# XMC1200 register map
Vendor: Infineon; File version: 1.3.0 (Reference Manual v1.3)
CPU: CM0 r0p0, little endian, no MPU, no FPU, 2 interrupt priority bits
Registers are 32-bit, read-write, reset 0x0 unless marked. A register's access mark holds for its fields unless they carry their own. Offsets are from the block's base; [hi:lo] are bit positions.

## NVM — NVM Unit
Base 0x40050000
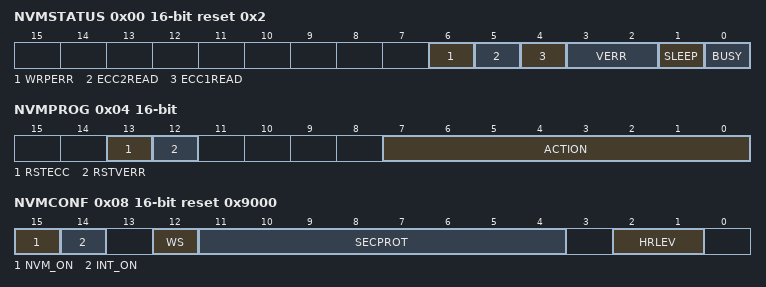
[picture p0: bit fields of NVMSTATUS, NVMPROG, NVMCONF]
0x00 NVMSTATUS 16-bit ro reset 0x2
  [6] WRPERR — Write Protocol Error
    0=No write protocol failure occurred; 1=At least one write protocol failure was detected
  [5] ECC2READ
    0=No ECC two bit failure during memory read operations; 1=At least one ECC two bit failure was detected
  [4] ECC1READ
    0=No ECC single bit failure occurred; 1=At least one ECC single bit failure was detected and corrected
  [3:2] VERR — Verify Error
    0=No fail bit; 1=One fail bit in one data block; 2=Two fail bits in two different data blocks; 3=Two or more fail bits in one data block, or three or more fail bits overall
  [1] SLEEP — Sleep Mode
    0=NVM not in sleep mode, and no sleep or wake up procedure in progress; 1=NVM in sleep mode, or busy due to a sleep or wake up procedure
  [0] BUSY
    0=The NVM is not busy. Memory reads from the cell array and register write accesses are possible.; 1=The NVM is busy. Memory reads and register write accesses are not possible.
0x04 NVMPROG 16-bit — NVM Programming Control Register
  [13] RSTECC — Reset ECC
    0=No action; 1=Reset of .ECCxREAD and NVMSTATUS.WRPERR
  [12] RSTVERR — Reset Verify Error
    0=No action; 1=Reset of .VERR
  [7:0] ACTION — ACTION: [VERIFY, ONE_SHOT, OPTYPE]
    0=Idle state, no action triggered. Writing 0x00 exits current mode.; 81=Start one-shot write operation with automatic verify; 145=Start one-shot write operation without verify; 97=Start continuous write operation with automatic verify of every write; 161=Start continuous write operation without verify; 146=Start one-shot page erase operation; 162=Start continuous page erase operation; 208=Start one-shot verify-only: Written data is compared to array content; 224=Start continuous verify-only: Written data is compared to array content
0x08 NVMCONF 16-bit reset 0x9000 — NVM Configuration Register
  [15] NVM_ON
    0=NVM is switched to or stays in sleep mode; 1=NVM is switched to or stays in normal mode
  [14] INT_ON — Interrupt On
    0=No NVM ready interrupts are generated; 1=NVM ready interrupts are generated
  [12] WS — Number of fixed Wait States
    0=0 fixed wait states; 1=1 fixed wait state
  [11:4] SECPROT — Sector Protection
  [2:1] HRLEV — Hardread Level
    0=Normal read; 1=Hardread written; 2=Hardread erased
0x48 CONFIG1 16-bit reset not defined — Configuration 1 Register
  [11] FIXWS — Wait States Scheme
    0=Const_0 (adaptive wait states.); 1=Const_1 (fixed wait states.)

## WDT — Watch Dog Timer
Base 0x40020000
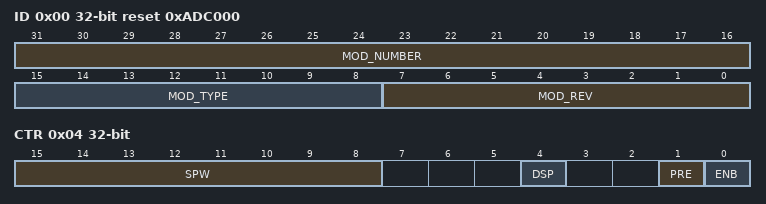
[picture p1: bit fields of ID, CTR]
0x00 ID ro reset 0xADC000 (reset mask 0xFFFFFF00) — WDT Module ID Register
  [31:16] MOD_NUMBER — Module Number Value
  [15:8] MOD_TYPE — Module Type
  [7:0] MOD_REV — Module Revision Number
0x04 CTR — WDT Control Register
  [15:8] SPW — Service Indication Pulse Width
  [4] DSP — Debug Suspend
  [1] PRE — Pre-warning
  [0] ENB — Enable
0x08 SRV wo — WDT Service Register
  [31:0] SRV — Service
0x0C TIM ro — WDT Timer Register
  [31:0] TIM — Timer Value
0x10 WLB — WDT Window Lower Bound Register
  [31:0] WLB — Window Lower Bound
0x14 WUB reset 0xFFFFFFFF — WDT Window Upper Bound Register
  [31:0] WUB — Window Upper Bound
0x18 WDTSTS ro — WDT Status Register
  [0] ALMS — Pre-warning Alarm
0x1C WDTCLR wo — WDT Clear Register
  [0] ALMC — Pre-warning Alarm

## RTC — Real Time Clock
Base 0x40010A00
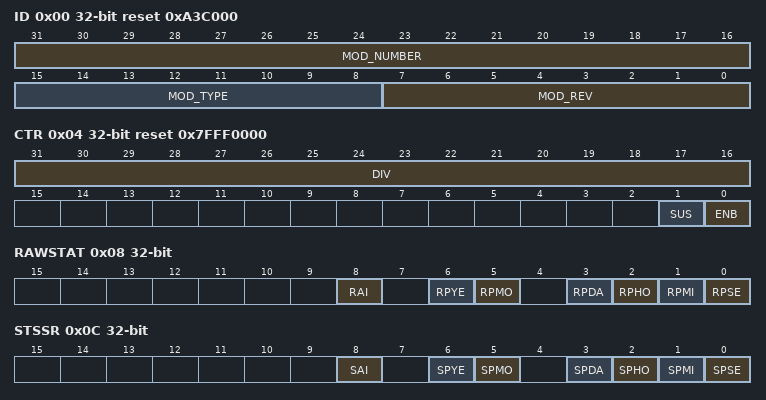
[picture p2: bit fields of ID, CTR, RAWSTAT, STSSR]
0x00 ID ro reset 0xA3C000 (reset mask 0xFFFFFF00) — RTC Module ID Register
  [31:16] MOD_NUMBER — Module Number Value
  [15:8] MOD_TYPE — Module Type
  [7:0] MOD_REV — Module Revision Number
0x04 CTR reset 0x7FFF0000 — RTC Control Register
  [31:16] DIV — Divider Value
  [1] SUS — Debug Suspend Control
  [0] ENB — RTC Module Enable
0x08 RAWSTAT ro — RTC Raw Service Request Register
  [8] RAI — Alarm Service Request
  [6] RPYE — Raw Periodic Years Service Request
  [5] RPMO — Raw Periodic Months Service Request
  [3] RPDA — Raw Periodic Days Service Request
  [2] RPHO — Raw Periodic Hours Service Request
  [1] RPMI — Raw Periodic Minutes Service Request
  [0] RPSE — Raw Periodic Seconds Service Request
0x0C STSSR ro — RTC Service Request Status Register
  [8] SAI — Alarm Service Request Status after masking
  [6] SPYE — Periodic Years Service Request Status after masking
  [5] SPMO — Periodic Months Service Request Status after masking
  [3] SPDA — Periodic Days Service Request Status after masking
  [2] SPHO — Periodic Hours Service Request Status after masking
  [1] SPMI — Periodic Minutes Service Request Status after masking
  [0] SPSE — Periodic Seconds Service Request Status after masking
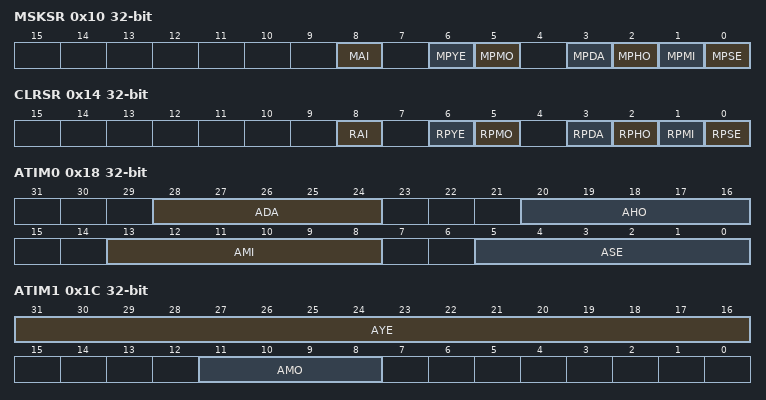
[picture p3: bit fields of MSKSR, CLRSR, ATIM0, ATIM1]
0x10 MSKSR — RTC Service Request Mask Register
  [8] MAI — Alarm Interrupt Mask
  [6] MPYE — Periodic Years Interrupt Mask
  [5] MPMO — Periodic Months Interrupt Mask
  [3] MPDA — Periodic Days Interrupt Mask
  [2] MPHO — Periodic Hours Interrupt Mask
  [1] MPMI — Periodic Minutes Interrupt Mask
  [0] MPSE — Periodic Seconds Interrupt Mask
0x14 CLRSR wo — RTC Clear Service Request Register
  [8] RAI — Raw Alarm Interrupt Clear
  [6] RPYE — Raw Periodic Years Interrupt Clear
  [5] RPMO — Raw Periodic Months Interrupt Clear
  [3] RPDA — Raw Periodic Days Interrupt Clear
  [2] RPHO — Raw Periodic Hours Interrupt Clear
  [1] RPMI — Raw Periodic Minutes Interrupt Clear
  [0] RPSE — Raw Periodic Seconds Interrupt Clear
0x18 ATIM0 — RTC Alarm Time Register 0
  [28:24] ADA — Alarm Days Compare Value
  [20:16] AHO — Alarm Hours Compare Value
  [13:8] AMI — Alarm Minutes Compare Value
  [5:0] ASE — Alarm Seconds Compare Value
0x1C ATIM1 — RTC Alarm Time Register 1
  [31:16] AYE — Alarm Year Compare Value
  [11:8] AMO — Alarm Month Compare Value
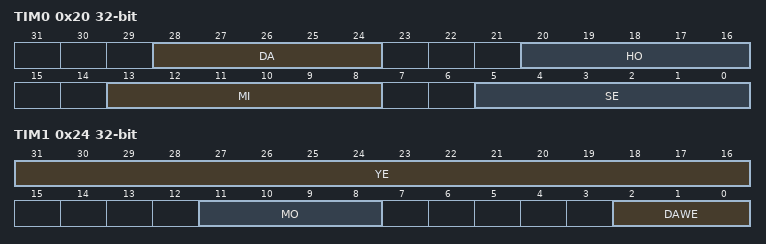
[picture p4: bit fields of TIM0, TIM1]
0x20 TIM0 — RTC Time Register 0
  [28:24] DA — Days Time Value
  [20:16] HO — Hours Time Value
  [13:8] MI — Minutes Time Value
  [5:0] SE — Seconds Time Value
0x24 TIM1 — RTC Time Register 1
  [31:16] YE — Year Time Value
  [11:8] MO — Month Time Value
  [2:0] DAWE — Days of Week Time Value
